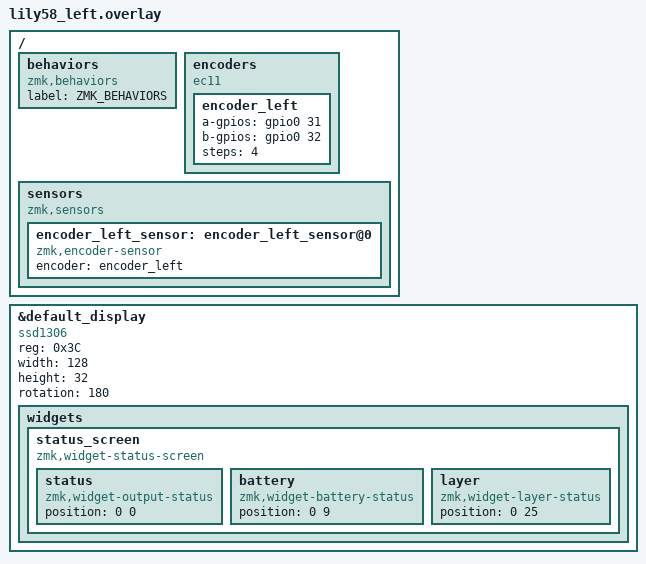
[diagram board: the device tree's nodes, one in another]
#include "../lily58.dtsi"

&default_display {
    compatible = "ssd1306";
    reg = <0x3C>;                    // I2C address
    width = <128>;
    height = <32>;
    rotation = <180>;
    status = "okay";

    widgets {
        status_screen {
            compatible = "zmk,widget-status-screen";
            status {
                compatible = "zmk,widget-output-status";
                position = <0 0>;
            };
            battery {
                compatible = "zmk,widget-battery-status";
                position = <0 9>;
            };
            layer {
                compatible = "zmk,widget-layer-status";
                position = <0 25>;
            };
        };
    };
};


/ {
    behaviors {
        compatible = "zmk,behaviors";
        label = "ZMK_BEHAVIORS";
    };
};


/ {
    // Encoder definition
    encoders {
        compatible = "ec11";
        status = "okay";
        encoder_left: encoder_left {
            // Using pin numbers 31 and 32 on GPIO controller 0
            a-gpios = <&gpio0 31 (GPIO_PULL_UP | GPIO_ACTIVE_HIGH)>;
            b-gpios = <&gpio0 32 (GPIO_PULL_UP | GPIO_ACTIVE_HIGH)>;
            steps = <4>; 
            status = "okay";
        };
    };
    
    // Sensor binding definition for the encoder
    sensors {
        compatible = "zmk,sensors";
        #address-cells = <1>;
        #size-cells = <0>;
        
        encoder_left_sensor: encoder_left_sensor@0 {
            compatible = "zmk,encoder-sensor";
            status = "okay";
            encoder = <&encoder_left>;
        };
    };

    behaviors {
        compatible = "zmk,behaviors";
        label = "ZMK_BEHAVIORS";
    };
};
